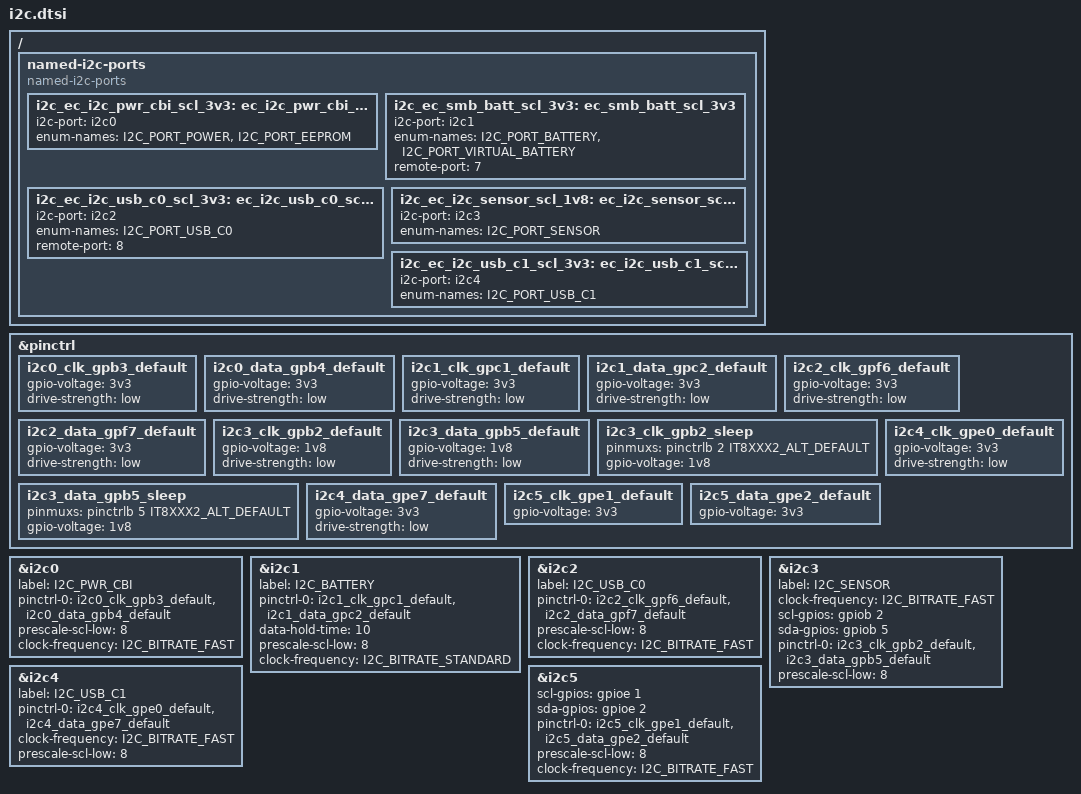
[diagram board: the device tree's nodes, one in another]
/* Copyright 2024 The ChromiumOS Authors
 * Use of this source code is governed by a BSD-style license that can be
 * found in the LICENSE file.
 */

/ {
	named-i2c-ports {
		compatible = "named-i2c-ports";

		i2c_ec_i2c_pwr_cbi_scl_3v3: ec_i2c_pwr_cbi_scl_3v3 {
			i2c-port = <&i2c0>;
			enum-names = "I2C_PORT_POWER", "I2C_PORT_EEPROM";
		};
		i2c_ec_smb_batt_scl_3v3: ec_smb_batt_scl_3v3 {
			i2c-port = <&i2c1>;
			enum-names = "I2C_PORT_BATTERY", "I2C_PORT_VIRTUAL_BATTERY";
			remote-port = <7>;
		};
		i2c_ec_i2c_usb_c0_scl_3v3: ec_i2c_usb_c0_scl_3v3 {
			i2c-port = <&i2c2>;
			enum-names = "I2C_PORT_USB_C0";
			remote-port = <8>;
		};
		i2c_ec_i2c_sensor_scl_1v8: ec_i2c_sensor_scl_1v8 {
			i2c-port = <&i2c3>;
			enum-names = "I2C_PORT_SENSOR";
		};
		i2c_ec_i2c_usb_c1_scl_3v3: ec_i2c_usb_c1_scl_3v3 {
			i2c-port = <&i2c4>;
			enum-names = "I2C_PORT_USB_C1";
		};
	};
};

&pinctrl {
	/* I2C property setting */
	i2c0_clk_gpb3_default: i2c0_clk_gpb3_default {
		gpio-voltage = "3v3";
		drive-strength = "low";
	};
	i2c0_data_gpb4_default: i2c0_data_gpb4_default {
		gpio-voltage = "3v3";
		drive-strength = "low";
	};
	i2c1_clk_gpc1_default: i2c1_clk_gpc1_default {
		gpio-voltage = "3v3";
		drive-strength = "low";
	};
	i2c1_data_gpc2_default: i2c1_data_gpc2_default {
		gpio-voltage = "3v3";
		drive-strength = "low";
	};
	i2c2_clk_gpf6_default: i2c2_clk_gpf6_default {
		gpio-voltage = "3v3";
		drive-strength = "low";
	};
	i2c2_data_gpf7_default: i2c2_data_gpf7_default {
		gpio-voltage = "3v3";
		drive-strength = "low";
	};
	i2c3_clk_gpb2_default: i2c3_clk_gpb2_default {
		gpio-voltage = "1v8";
		drive-strength = "low";
	};
	i2c3_data_gpb5_default: i2c3_data_gpb5_default {
		gpio-voltage = "1v8";
		drive-strength = "low";
	};
	i2c3_clk_gpb2_sleep: i2c3_clk_gpb2_sleep {
		pinmuxs = <&pinctrlb 2 IT8XXX2_ALT_DEFAULT>;
		gpio-voltage = "1v8";
	};
	i2c3_data_gpb5_sleep: i2c3_data_gpb5_sleep {
		pinmuxs = <&pinctrlb 5 IT8XXX2_ALT_DEFAULT>;
		gpio-voltage = "1v8";
	};
	i2c4_clk_gpe0_default: i2c4_clk_gpe0_default {
		gpio-voltage = "3v3";
		drive-strength = "low";
	};
	i2c4_data_gpe7_default: i2c4_data_gpe7_default {
		gpio-voltage = "3v3";
		drive-strength = "low";
	};
	i2c5_clk_gpe1_default: i2c5_clk_gpe1_default {
		gpio-voltage = "3v3";
	};
	i2c5_data_gpe2_default: i2c5_data_gpe2_default {
		gpio-voltage = "3v3";
	};
};

 &i2c0 {
	status = "okay";
	label = "I2C_PWR_CBI";
	pinctrl-0 = <&i2c0_clk_gpb3_default
		&i2c0_data_gpb4_default>;
	pinctrl-names = "default";
	prescale-scl-low = <8>;
	clock-frequency = <I2C_BITRATE_FAST>;
};

&i2c1 {
	label = "I2C_BATTERY";
	status = "okay";
	pinctrl-0 = <&i2c1_clk_gpc1_default
		&i2c1_data_gpc2_default>;
	pinctrl-names = "default";
	data-hold-time = <10>;
	prescale-scl-low = <8>;
	clock-frequency = <I2C_BITRATE_STANDARD>;
};

&i2c2 {
	label = "I2C_USB_C0";
	status = "okay";
	pinctrl-0 = <&i2c2_clk_gpf6_default
		&i2c2_data_gpf7_default>;
	pinctrl-names = "default";
	prescale-scl-low = <8>;
	clock-frequency = <I2C_BITRATE_FAST>;
};

&i2c3 {
	label = "I2C_SENSOR";
	clock-frequency = <I2C_BITRATE_FAST>;
	status = "okay";
	scl-gpios = <&gpiob 2 0>;
	sda-gpios = <&gpiob 5 0>;
	pinctrl-0 = <&i2c3_clk_gpb2_default
		&i2c3_data_gpb5_default>;
	pinctrl-names = "default";
	prescale-scl-low = <8>;
};

&i2c4 {
	label = "I2C_USB_C1";
	status = "okay";
	pinctrl-0 = <&i2c4_clk_gpe0_default
		&i2c4_data_gpe7_default>;
	pinctrl-names = "default";
	clock-frequency = <I2C_BITRATE_FAST>;
	prescale-scl-low = <8>;
};

&i2c5 {
	status = "okay";
	scl-gpios = <&gpioe 1 0>;
	sda-gpios = <&gpioe 2 0>;
	pinctrl-0 = <&i2c5_clk_gpe1_default
		&i2c5_data_gpe2_default>;
	pinctrl-names = "default";
	prescale-scl-low = <8>;
	clock-frequency = <I2C_BITRATE_FAST>;
};
